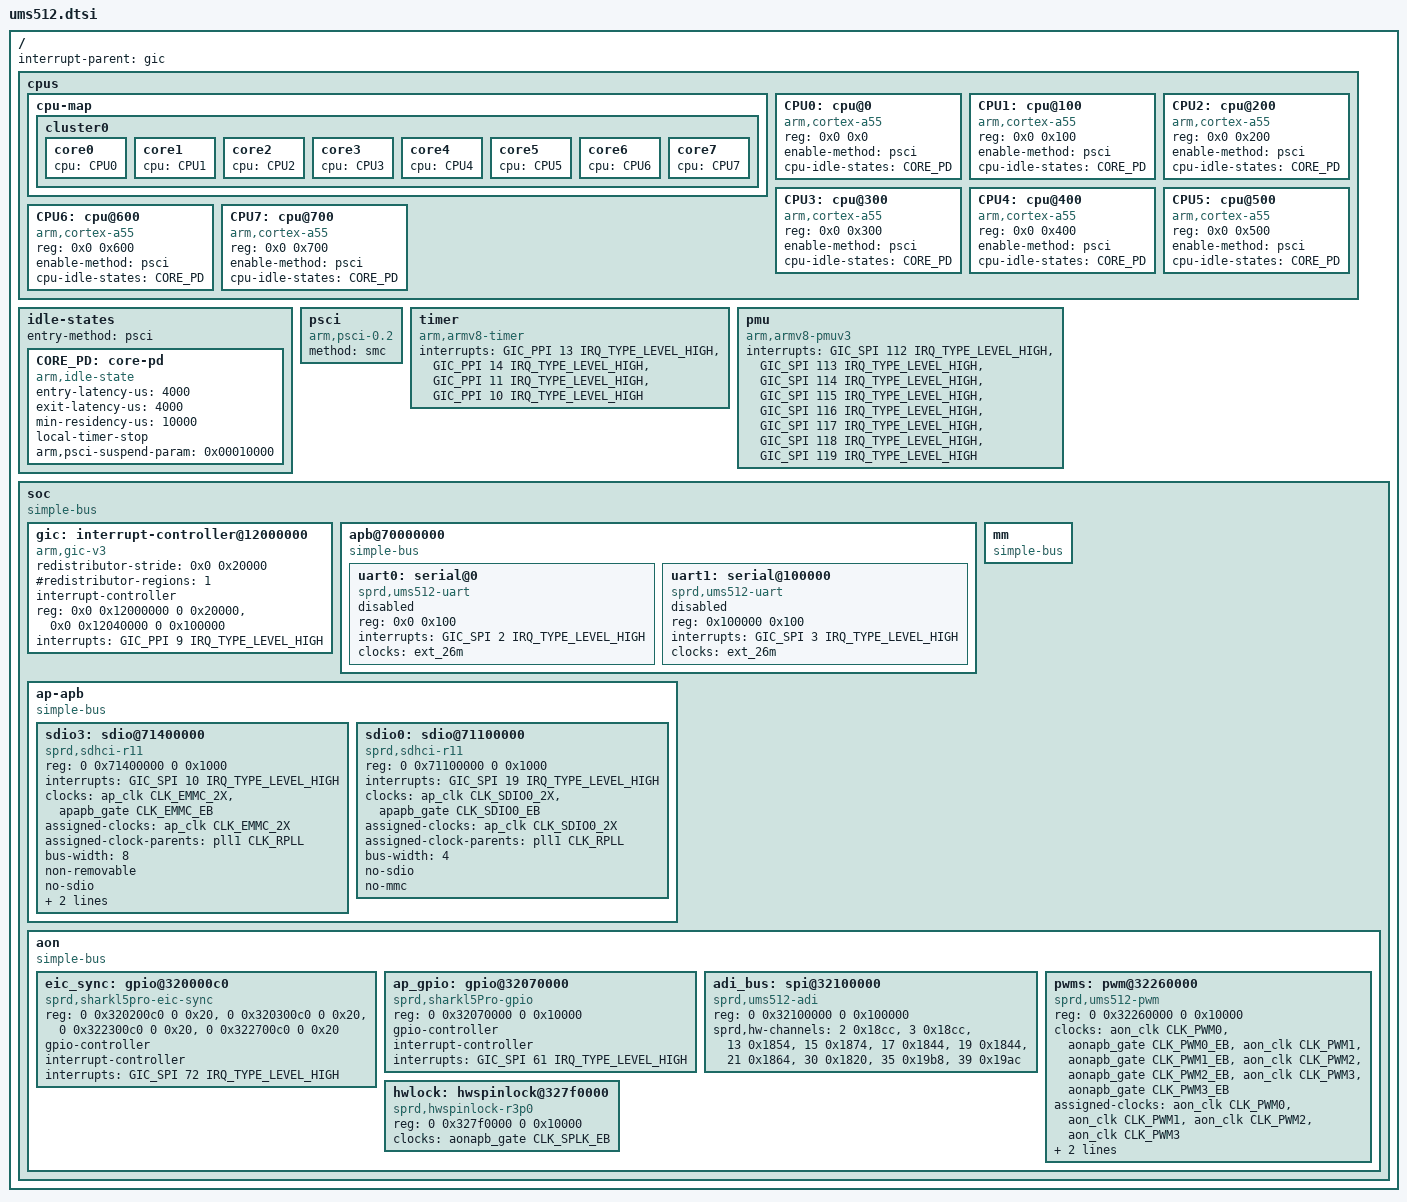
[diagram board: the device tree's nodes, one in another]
// SPDX-License-Identifier: GPL-2.0-only
/*
 * Unisoc UMS512 SoC DTS file
 *
 * Copyright (C) 2021, Unisoc Inc.
 */

#include <dt-bindings/clock/sprd,ums512-clk.h>
#include <dt-bindings/interrupt-controller/arm-gic.h>

/ {
	interrupt-parent = <&gic>;
	#address-cells = <2>;
	#size-cells = <2>;

	cpus {
		#address-cells = <2>;
		#size-cells = <0>;

		cpu-map {
			cluster0 {
				core0 {
					cpu = <&CPU0>;
				};
				core1 {
					cpu = <&CPU1>;
				};
				core2 {
					cpu = <&CPU2>;
				};
				core3 {
					cpu = <&CPU3>;
				};
				core4 {
					cpu = <&CPU4>;
				};
				core5 {
					cpu = <&CPU5>;
				};
				core6 {
					cpu = <&CPU6>;
				};
				core7 {
					cpu = <&CPU7>;
				};
			};
		};

		CPU0: cpu@0 {
			device_type = "cpu";
			compatible = "arm,cortex-a55";
			reg = <0x0 0x0>;
			enable-method = "psci";
			cpu-idle-states = <&CORE_PD>;
		};

		CPU1: cpu@100 {
			device_type = "cpu";
			compatible = "arm,cortex-a55";
			reg = <0x0 0x100>;
			enable-method = "psci";
			cpu-idle-states = <&CORE_PD>;
		};

		CPU2: cpu@200 {
			device_type = "cpu";
			compatible = "arm,cortex-a55";
			reg = <0x0 0x200>;
			enable-method = "psci";
			cpu-idle-states = <&CORE_PD>;
		};

		CPU3: cpu@300 {
			device_type = "cpu";
			compatible = "arm,cortex-a55";
			reg = <0x0 0x300>;
			enable-method = "psci";
			cpu-idle-states = <&CORE_PD>;
		};

		CPU4: cpu@400 {
			device_type = "cpu";
			compatible = "arm,cortex-a55";
			reg = <0x0 0x400>;
			enable-method = "psci";
			cpu-idle-states = <&CORE_PD>;
		};

		CPU5: cpu@500 {
			device_type = "cpu";
			compatible = "arm,cortex-a55";
			reg = <0x0 0x500>;
			enable-method = "psci";
			cpu-idle-states = <&CORE_PD>;
		};

		CPU6: cpu@600 {
			device_type = "cpu";
			compatible = "arm,cortex-a55";
			reg = <0x0 0x600>;
			enable-method = "psci";
			cpu-idle-states = <&CORE_PD>;
		};

		CPU7: cpu@700 {
			device_type = "cpu";
			compatible = "arm,cortex-a55";
			reg = <0x0 0x700>;
			enable-method = "psci";
			cpu-idle-states = <&CORE_PD>;
		};
	};

	idle-states {
		entry-method = "psci";
		CORE_PD: core-pd {
			compatible = "arm,idle-state";
			entry-latency-us = <4000>;
			exit-latency-us = <4000>;
			min-residency-us = <10000>;
			local-timer-stop;
			arm,psci-suspend-param = <0x00010000>;
		};
	};

	psci {
		compatible = "arm,psci-0.2";
		method = "smc";
	};

	timer {
		compatible = "arm,armv8-timer";
		interrupts = <GIC_PPI 13 IRQ_TYPE_LEVEL_HIGH>, /* Physical Secure PPI */
			     <GIC_PPI 14 IRQ_TYPE_LEVEL_HIGH>, /* Physical Non-Secure PPI */
			     <GIC_PPI 11 IRQ_TYPE_LEVEL_HIGH>, /* Virtual PPI */
			     <GIC_PPI 10 IRQ_TYPE_LEVEL_HIGH>; /* Hipervisor PPI */
	};

	pmu {
		compatible = "arm,armv8-pmuv3";
		interrupts = <GIC_SPI 112 IRQ_TYPE_LEVEL_HIGH>,
			     <GIC_SPI 113 IRQ_TYPE_LEVEL_HIGH>,
			     <GIC_SPI 114 IRQ_TYPE_LEVEL_HIGH>,
			     <GIC_SPI 115 IRQ_TYPE_LEVEL_HIGH>,
			     <GIC_SPI 116 IRQ_TYPE_LEVEL_HIGH>,
			     <GIC_SPI 117 IRQ_TYPE_LEVEL_HIGH>,
			     <GIC_SPI 118 IRQ_TYPE_LEVEL_HIGH>,
			     <GIC_SPI 119 IRQ_TYPE_LEVEL_HIGH>;
	};

	soc: soc {
		compatible = "simple-bus";
		#address-cells = <2>;
		#size-cells = <2>;
		ranges;

		gic: interrupt-controller@12000000 {
			compatible = "arm,gic-v3";
			#interrupt-cells = <3>;
			#address-cells = <2>;
			#size-cells = <2>;
			ranges;
			redistributor-stride = <0x0 0x20000>;	/* 128KB stride */
			#redistributor-regions = <1>;
			interrupt-controller;
			reg = <0x0 0x12000000 0 0x20000>,	/* GICD */
			      <0x0 0x12040000 0 0x100000>;	/* GICR */
			interrupts = <GIC_PPI 9 IRQ_TYPE_LEVEL_HIGH>;
		};

		apb@70000000 {
			compatible = "simple-bus";
			#address-cells = <1>;
			#size-cells = <1>;
			ranges = <0 0x0 0x70000000 0x10000000>;

			uart0: serial@0 {
				compatible = "sprd,ums512-uart",
					     "sprd,sc9836-uart";
				reg = <0x0 0x100>;
				interrupts = <GIC_SPI 2 IRQ_TYPE_LEVEL_HIGH>;
				clocks = <&ext_26m>;
				status = "disabled";
			};

			uart1: serial@100000 {
				compatible = "sprd,ums512-uart",
					     "sprd,sc9836-uart";
				reg = <0x100000 0x100>;
				interrupts = <GIC_SPI 3 IRQ_TYPE_LEVEL_HIGH>;
				clocks = <&ext_26m>;
				status = "disabled";
			};
		};

		ap-apb {
			compatible = "simple-bus";
			#address-cells = <2>;
			#size-cells = <2>;
			ranges;

			sdio3: sdio@71400000 {
				compatible = "sprd,sdhci-r11";
				reg = <0 0x71400000 0 0x1000>;
				interrupts = <GIC_SPI 10 IRQ_TYPE_LEVEL_HIGH>;
				clock-names = "sdio", "enable";
				clocks = <&ap_clk CLK_EMMC_2X>,
					 <&apapb_gate CLK_EMMC_EB>;
				assigned-clocks = <&ap_clk CLK_EMMC_2X>;
				assigned-clock-parents = <&pll1 CLK_RPLL>;

				bus-width = <8>;
				non-removable;
				no-sdio;
				no-sd;
				cap-mmc-hw-reset;
			};

			sdio0: sdio@71100000 {
				compatible = "sprd,sdhci-r11";
				reg = <0 0x71100000 0 0x1000>;
				interrupts = <GIC_SPI 19 IRQ_TYPE_LEVEL_HIGH>;
				clock-names = "sdio", "enable";
				clocks = <&ap_clk CLK_SDIO0_2X>,
					 <&apapb_gate CLK_SDIO0_EB>;
				assigned-clocks = <&ap_clk CLK_SDIO0_2X>;
				assigned-clock-parents = <&pll1 CLK_RPLL>;

				bus-width = <4>;
				no-sdio;
				no-mmc;
			};
		};

		mm: mm {
			compatible = "simple-bus";
			#address-cells = <2>;
			#size-cells = <2>;
			ranges;

		};

		aon: aon {
			compatible = "simple-bus";
			#address-cells = <2>;
			#size-cells = <2>;
			ranges;

			eic_sync: gpio@320000c0 {
				compatible = "sprd,sharkl5pro-eic-sync", "sprd,sc9860-eic-sync";
				reg = <0 0x320200c0 0 0x20>,
				      <0 0x320300c0 0 0x20>,
				      <0 0x322300c0 0 0x20>,
				      <0 0x322700c0 0 0x20>;
				gpio-controller;
				#gpio-cells = <2>;
				interrupt-controller;
				#interrupt-cells = <2>;
				interrupts = <GIC_SPI 72 IRQ_TYPE_LEVEL_HIGH>;
			};

			ap_gpio: gpio@32070000 {
				compatible = "sprd,sharkl5Pro-gpio", "sprd,sc9860-gpio";
				reg = <0 0x32070000 0 0x10000>;
				gpio-controller;
				#gpio-cells = <2>;
				interrupt-controller;
				#interrupt-cells = <2>;
				interrupts = <GIC_SPI 61 IRQ_TYPE_LEVEL_HIGH>;
			};

			adi_bus: spi@32100000 {
				compatible = "sprd,ums512-adi";
				reg = <0 0x32100000 0 0x100000>;
				#address-cells = <1>;
				#size-cells = <0>;
				sprd,hw-channels = <2 0x18cc>, <3 0x18cc>, <13 0x1854>, <15 0x1874>,
					<17 0x1844>,<19 0x1844>, <21 0x1864>, <30 0x1820>,
					<35 0x19b8>, <39 0x19ac>;
			};

			pwms: pwm@32260000 {
				compatible = "sprd,ums512-pwm";
				reg = <0 0x32260000 0 0x10000>;
				clock-names = "pwm0", "enable0",
					      "pwm1", "enable1",
						  "pwm2", "enable2",
					      "pwm3", "enable3";
				clocks = <&aon_clk CLK_PWM0>, <&aonapb_gate CLK_PWM0_EB>,
					 <&aon_clk CLK_PWM1>, <&aonapb_gate CLK_PWM1_EB>,
					 <&aon_clk CLK_PWM2>, <&aonapb_gate CLK_PWM2_EB>,
					 <&aon_clk CLK_PWM3>, <&aonapb_gate CLK_PWM3_EB>;
				assigned-clocks = <&aon_clk CLK_PWM0>,
						  <&aon_clk CLK_PWM1>,
						  <&aon_clk CLK_PWM2>,
						  <&aon_clk CLK_PWM3>;
				assigned-clock-parents = <&ext_26m>,
							 <&ext_26m>,
							 <&ext_26m>,
							 <&ext_26m>;
				#pwm-cells = <2>;
			};

			hwlock: hwspinlock@327f0000 {
				compatible = "sprd,hwspinlock-r3p0";
				reg = <0 0x327f0000 0 0x10000>;
				#hwlock-cells = <1>;
				clock-names = "enable";
				clocks = <&aonapb_gate CLK_SPLK_EB>;
			};
		};
	};
};

/* Include other IP modules */
#include "glbreg.dtsi"
#include "clock.dtsi"
#include "coresight.dtsi"
#include "dispc.dtsi"
#include "qos.dtsi"
#include "usb.dtsi"

